# iqn_dio2 register map
Vendor: Texas Instruments
Peripheral module from a debugger description file (folder Keystone2).
Registers are 32-bit, read-only, no defined reset value unless marked. A register's access mark holds for its fields unless they carry their own. Offsets are as the file gives them; lines under a group give offsets from that group; [hi:lo] are bit positions; {n}, {i} and the like mark numbered series; 'fields as' and 'values as' point back to an identical list; <NAME> marks a mode.

## IQN_DIO2 (part 1 of 2)
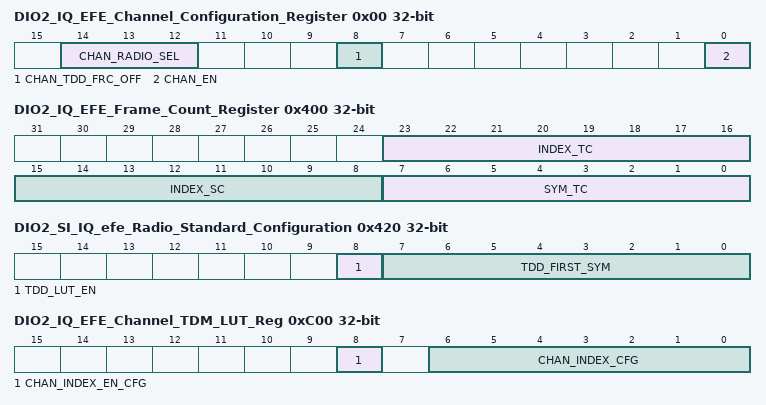
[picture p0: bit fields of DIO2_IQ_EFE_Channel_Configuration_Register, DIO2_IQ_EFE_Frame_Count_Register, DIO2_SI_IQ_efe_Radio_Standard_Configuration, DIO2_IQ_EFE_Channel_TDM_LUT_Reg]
0x00 DIO2_IQ_EFE_Channel_Configuration_Register rw — (1 of 1, stride 0)
  [14:12] CHAN_RADIO_SEL — Assigns each channel to one of eight radio standard groups. i.e. radio standard 0 may be LTE 20MHz
  [8] CHAN_TDD_FRC_OFF — Alternate TDD mode for controlling TDD also used for GSM Base Band Hopping. APP SW controls updates this bit each symbol of time to control whether the next symbol will be TDD OFF. TDD OFF channels generate no Ingress DMA traffic and expect no Egress DMA
  [0] CHAN_EN — Enable channel
0x200 DIO2_IQ_EFE_Configuration_Register rw — (1 of 1, stride 0)
  [0] LOOPBACK_EN — (TI use Only) 0x1: Ingress data from ICC is looped back to Egress data to ICC. DMA traffic is unused. (i.e. for purpose of early DFE only testing)
0x240 DIO2_IQ_EFE_Global_Enable_Set_Reg wo — (1 of 1, stride 0)
  [31:0] DONT_CARE — A write of any value to this register which sets (enables) global enable
0x244 DIO2_IQ_EFE_Global_Enable_Clear_Reg wo — (1 of 1, stride 0)
  [31:0] DONT_CARE — A write of any value to this register which clears (enables) global enable
0x248 DIO2_IQ_EFE_Global_Enable_Status — (1 of 1, stride 0)
  [0] ENABLE — 0x1: efe_ON 0x0:efe_OFF
0x260 DIO2_IQ_EFE_Channel_ON_Status_Reg — (1 of 1, stride 0)
  [15:0] CHAN_ON — 0x1: CHAN_ON 0x0:CHAN_OFF
0x280 DIO2_IQ_EFE_IN_Packet_Status_Registers — (1 of 1, stride 0)
  [15:0] IN_PKT — 0x1: IN_PKT 0x0:OUT_PKT
0x2A0 DIO2_IQ_EFE_DMA_SYNC_Status_Registers — (1 of 1, stride 0)
  [15:0] DMA_SYNC — 0x1: DMA synchronized to radio timing for this channel 0x0:DMA not synchronized to radio timing for this channel. Channel is in in re-sync mode.
0x400 DIO2_IQ_EFE_Frame_Count_Register rw — (1 of 1, stride 0)
  [23:16] INDEX_TC — Radio Framing Counter. Index Counter Terminal Count. Index counter terminal count which is the last value of the Index Counter before it wraps. For simple use case, program same as frm_sym_tc.
  [15:8] INDEX_SC — Radio Framing Counter. Index Counter Starting Location. Starting location of the Sample Terminal Count LUT loaded into the Index Counter when it first starts and each time it wraps. Depending on the radio standard, the index will wrap once per radio frame
  [7:0] SYM_TC — Radio Framing Counter. Symbol Count. Number of symbols per frame programmed as a terminal count.
0x420 DIO2_SI_IQ_efe_Radio_Standard_Configuration rw — (1 of 1, stride 0)
  [8] TDD_LUT_EN — Enable TDD
  [7:0] TDD_FIRST_SYM — Selects first symbol to start TDD
{0x440+0x20*i} DIO2_IQ_efe_Radio_Standard_{i}_TDD_ENABLE_LUT rw (i=0..7) — (1 of 1, stride 0)
  [31:0] TDD_EN — enables/disables DMA of whole symbols (PktDMA packets). Program as 0xffff for most applications.
0x600 DIO2_IQ_EFE_Channel_AXC_Offset_Reg rw — (1 of 16, stride 4)
  [19:0] AXC_OFFSET — AxC-by-AxC delay control. Allows different timing alignments for each AxC. DIO, AID applicactions this is a 4 sample offset relatvie to the group or TDM of AxC. AIL CPRI, this is a sample offset relative to the CPRI AxC Group. AIL OBSAI, this is a Radio
0x800 DIO2_IQ_EFE_AxC_Framing_Sample_Terminal_Count rw — (1 of 256, stride 4)
  [17:0] SAMP_TC — Radio Framing Counter. Number of samples (4 Bytes) per radio symbol programmed as a terminal count
0xC00 DIO2_IQ_EFE_Channel_TDM_LUT_Reg rw — (1 of 256, stride 4)
  [8] CHAN_INDEX_EN_CFG — TDM Channel Index LUT Enable
  [6:0] CHAN_INDEX_CFG — TDM Channel Index
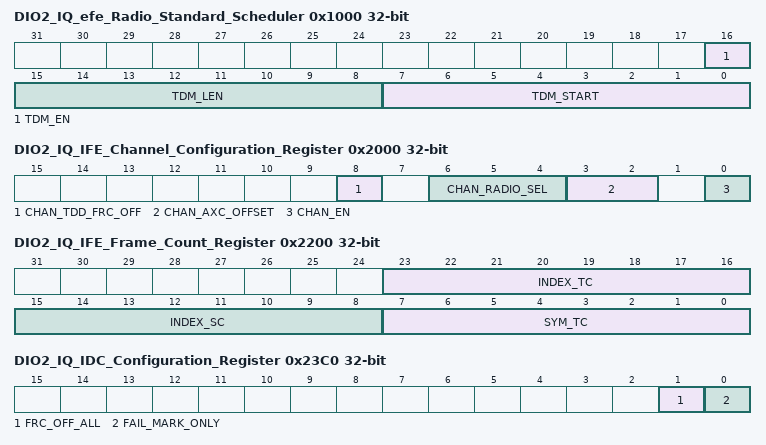
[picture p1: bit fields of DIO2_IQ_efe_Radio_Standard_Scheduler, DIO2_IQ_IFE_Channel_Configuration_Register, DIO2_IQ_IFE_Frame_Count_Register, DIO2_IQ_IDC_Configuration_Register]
0x1000 DIO2_IQ_efe_Radio_Standard_Scheduler rw — (1 of 1, stride 0)
  [16] TDM_EN — EFE Scheculer Enable TDM
  [15:8] TDM_LEN — EFE Scheduler TDM Length
  [7:0] TDM_START — EFE Scheduler TDM Starting address in LUT
0x2000 DIO2_IQ_IFE_Channel_Configuration_Register rw — (1 of 1, stride 0)
  [8] CHAN_TDD_FRC_OFF — Forces a channel into the TDD OFF state on the next symbol after it is set to a 1 regardless of the TDD configuration of the radio standard variant the channel is assigned to.
  [6:4] CHAN_RADIO_SEL — Radio Standard Select
  [3:2] CHAN_AXC_OFFSET — AxC Offset
  [0] CHAN_EN — Enable channel
0x2200 DIO2_IQ_IFE_Frame_Count_Register rw — (1 of 1, stride 0)
  [23:16] INDEX_TC — Radio Framing Counter. Index Counter Terminal Count. Index counter terminal count which is the last value of the Index Counter before it wraps. For simple use case, program same as frm_sym_tc.
  [15:8] INDEX_SC — Radio Framing Counter. Index Counter Starting Location. Starting location of the Sample Terminal Count LUT loaded into the Index Counter when it first starts and each time it wraps.
  [7:0] SYM_TC — Radio Framing Counter. Symbol Count. Number of symbols per frame programmed as a terminal count.
0x2220 DIO2_IQ_IFE_Radio_Standard_Configuration rw — (1 of 1, stride 0)
  [0] TDD_LUT_EN — Enable TDD
{0x2240+0x20*i} DIO2_IQ_IFE_Radio_Standard_{i}_TDD_ENABLE_LUT rw (i=0..7) — (1 of 1, stride 0)
  fields as DIO2_IQ_efe_Radio_Standard_0_TDD_ENABLE_LUT
0x2340 DIO2_IQ_IFE_Global_Enable_Set_Reg wo — (1 of 1, stride 0)
  fields as DIO2_IQ_EFE_Global_Enable_Set_Reg
0x2344 DIO2_IQ_IFE_Global_Enable_Clear_Reg wo — (1 of 1, stride 0)
  fields as DIO2_IQ_EFE_Global_Enable_Clear_Reg
0x2348 DIO2_IQ_IFE_Global_Enable_Status — (1 of 1, stride 0)
  [0] ENABLE — 0x1: ife_ON 0x0:ife_OFF
0x2350 DIO2_IQ_IFE_Channel_ON_Status_Reg — (1 of 1, stride 0)
  [15:0] CHAN_ON — 0x1: CHAN_ON 0x0:CHAN_OFF
0x2360 DIO2_IQ_IFE_IN_Packet_Status_Registers — (1 of 1, stride 0)
  [15:0] IN_PKT — 0x1: IN_PKT 0x0:OUT_PKT
0x2384 DIO2_IQ_IDC_Status_Register — (1 of 1, stride 0)
  [0] EMPTY — Empty indicator for both the PSI Staging FIFO and the CDC FIFO
0x2390 DIO2_IQ_IDC_In_Packet_Status_Register — (1 of 1, stride 0)
  [15:0] INPKT — Per-channel in packet status bits where a 0 indicates that the channel is not actively processing a packet and a 1 indicates that it is actively processing a packet. The inpkt to channel assignment is such that inpkt\[0\] is associated with channel 0 and
0x23C0 DIO2_IQ_IDC_Configuration_Register rw — (1 of 1, stride 0)
  [1] FRC_OFF_ALL — Forces off all Ingress channels without waiting for an end of symbol or time slot. All open packets are automatically closed by creating an EOP for each open packet
  [0] FAIL_MARK_ONLY — Controls how the IDC handles packet errors detected by IFE
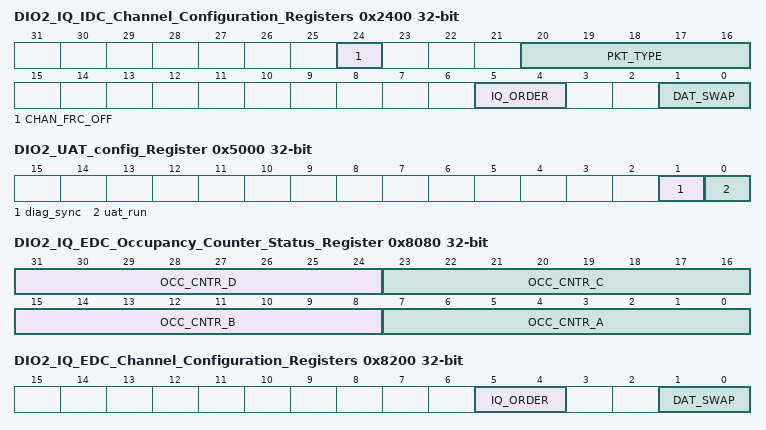
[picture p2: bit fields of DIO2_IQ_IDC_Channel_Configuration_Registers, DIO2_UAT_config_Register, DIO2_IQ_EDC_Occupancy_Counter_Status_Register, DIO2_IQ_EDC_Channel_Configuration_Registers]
0x2400 DIO2_IQ_IDC_Channel_Configuration_Registers rw — (1 of 1, stride 0)
  [24] CHAN_FRC_OFF — Forces off all channel without waiting for an end of symbol or time slot. If channel has an open packet it is automatically closed by creating an EOP
  [20:16] PKT_TYPE — Programmable packet type that is inserted into pkt_type field of PKTDMA Info Word 0.
  [5:4] IQ_ORDER — IQ swapping control.
  [1:0] DAT_SWAP — Byte swapping control.
0x2800 DIO2_IQ_IFE_AxC_Framing_Sample_Terminal_Count rw — (1 of 256, stride 4)
  fields as DIO2_IQ_EFE_AxC_Framing_Sample_Terminal_Count
0x5000 DIO2_UAT_config_Register rw — (1 of 1, stride 0)
  [1] diag_sync — diag_sync = 1 starts the BCN and RAD counters if uat_run is set and an AT sync is received. This is only used in simulation and for diagnostics
  [0] uat_run — UAT run starts the BCN and RAD counters free running
0x5004 DIO2_UAT_BCN_terminal_count_Register rw — (1 of 1, stride 0)
  [24:0] val — UAT BCN terminal count. BCN counts from zero to this limit and wraps to zero. Program as 2,457,599 for sys_clk=245.76MHz and 3,071,999 for sys_clk=307.2MHz
0x5008 DIO2_UAT_BCN_offset_Register rw — (1 of 1, stride 0)
  [24:0] val — Offset correction to the raw uAT BCN counter. Used to correct the alignment of the local uAT BCN to the master AT2 BCN. BCN is initially randomly started. SW uses uat_sync_bcn_capture_sts rd_val to calculate offset correction factor. This correction
0x500C DIO2_UAT_SYNC_BCN_capture_Register — (1 of 1, stride 0)
  [24:0] rd_val — uAT raw BCN value captured each frame boundary of AT2 master BCN. Used to calculate uAT BCN offset value for the purpose of aligning uAT to AT2 BCN.
0x5080 DIO2_UAT_RADT_terminal_count_Register rw — (1 of 8, stride 16)
  [24:0] val — UAT RADT terminal count. (i.e. 2,457,599 for WCDMA with sys_clk=245.76MHz)
0x5084 DIO2_UAT_RADT_offset_Register rw — (1 of 8, stride 16)
  [24:0] val — UAT RADT offset. Value which is added to the raw RADT as a timing correction. RadT is initially randomly started, SW uses radt_capture value to calculate offset correction factor. This correction factor will be Frame size
0x5088 DIO2_UAT_SYNC_RADT_capture_Register — (1 of 8, stride 16)
  [24:0] rd_val — UAT RADT sync capture captures the offset RADT count when a uat_mst_slv_sync from the AT occurs. Used by SW to determine correct RADT offset to apply.
0x5100 DIO2_UAT_RADT_terminal_count_Register rw — (1 of 8, stride 16)
  fields as DIO2_UAT_RADT_terminal_count_Register
0x5104 DIO2_UAT_RADT_offset_Register rw — (1 of 8, stride 16)
  fields as DIO2_UAT_RADT_offset_Register
0x5108 DIO2_UAT_SYNC_RADT_capture_Register — (1 of 8, stride 16)
  fields as DIO2_UAT_SYNC_RADT_capture_Register
0x5200 DIO2_UAT_RADT_event_compare_Register rw — (1 of 22, stride 8)
  [24:0] val — UAT RADT event compare per RADT. When compare value equals RADT count, frame rate event is generated. Also periodic event (i.e. 4SAMP) is started. The 0 to 7 are for si egress, 8 to 15 for si ingress, 16 to 18 for dio egress, 19 to 21 for dio ingress
0x5204 DIO2_UAT_RADT_event_clock_count_tc_Register rw — (1 of 22, stride 8)
  [15:0] val — UAT RADT event clock counter terminal count controls spacing of the periodic strobe (i.e. 4SAMP). Once the uat_evt_radt_cmp_cfg equals the RADT, the period strobe will fire and re-fire every time a clock counter reaches this terminal count. The The 0 to 7
0x5300 DIO2_UAT_DIO_egress_RADT_terminal_count rw — (1 of 3, stride 16)
  [24:0] val — (DIO use only) UAT DIO egress RADT terminal count. (i.e. 2,457,599 for WCDMA with sys_clk=245.76MHz)
0x5304 DIO2_UAT_DIO_egress_RADT_offset_Register rw — (1 of 3, stride 16)
  [24:0] val — (DIO use only) UAT DIO egress RADT offset. Value which is added to the raw RADT as a timing correction. RadT is initially randomly started, SW uses radt_capture value to calculate offset correction factor. This correction factor will be Frame size
0x5308 DIO2_UAT_SYNC_DIO_egress_RADT_capture_Register — (1 of 3, stride 16)
  [24:0] rd_val — (DIO use only)UAT DIO egress RADT sync capture captures the offset RADT count when a uat_mst_slv_sync from the AT occurs. Used by SW to determine correct RADT offset to apply.
0x5340 DIO2_UAT_DIO_ingress_RADT_terminal_count rw — (1 of 3, stride 16)
  [24:0] val — (DIO use only) UAT DIO ingress RADT terminal count. (i.e. 2,457,599 for WCDMA with sys_clk=245.76MHz)
0x5344 DIO2_UAT_DIO_ingress_RADT_offset_Register rw — (1 of 3, stride 16)
  [24:0] val — (DIO use only) UAT DIO ingress RADT offset. Value which is added to the raw RADT as a timing correction. RadT is initially randomly started, SW uses radt_capture value to calculate offset correction factor. This correction factor will be Frame size
0x5348 DIO2_UAT_SYNC_DIO_ingress_RADT_capture_Register — (1 of 3, stride 16)
  [24:0] rd_val — (DIO use only) UAT DIO ingress RADT sync capture captures the offset.
0x8000 DIO2_IQ_EDC_Configuration_Register rw — (1 of 1, stride 0)
  [0] PSI_ERR_CHK_DISABLE — Controls how the EDC handles packet errors detected by efe
0x8004 DIO2_IQ_EDC_SOP_Counter_Status_Register — (1 of 1, stride 0)
  [23:0] SOP_CNT — Count of the number of SOPs seen by the IQ EDC
0x8008 DIO2_IQ_EDC_EOP_Counter_Status_Register — (1 of 1, stride 0)
  [23:0] EOP_CNT — Count of the number of EOPs seen by the IQ EDC
0x8080 DIO2_IQ_EDC_Occupancy_Counter_Status_Register — (1 of 1, stride 0)
  [31:24] OCC_CNTR_D — Occupancy Counter for register D for this address
  [23:16] OCC_CNTR_C — Occupancy Counter for register C for this address
  [15:8] OCC_CNTR_B — Occupancy Counter for register B for this address
  [7:0] OCC_CNTR_A — Occupancy Counter for register A for this address
0x8200 DIO2_IQ_EDC_Channel_Configuration_Registers rw — (1 of 1, stride 0)
  [5:4] IQ_ORDER — IQ swapping control.
  [1:0] DAT_SWAP — Byte swapping control.
0xA000 DIO2_IQ_IDC_Rate_Control_Configuration_Register rw — (1 of 1, stride 0)
  [3:0] RATE — Rate Controller will allow the IDC to create RATE+1 active requests on the PSI bus within a 32 clock cycle window. As an example, a value of 7 will allow the IDC to create 8 active requests within a 32-clock cycle window which uses 25% of the PSI bus.
0xA004 DIO2_IQ_IDC_SOP_Counter_Register — (1 of 1, stride 0)
  [23:0] SOP_CNT — Wrapping count of SOPs sent on PSI.
0xA008 DIO2_IQ_IDC_EOP_Counter_Register — (1 of 1, stride 0)
  [23:0] EOP_CNT — Wrapping count of EOPs sent on PSI.
0x10000 DIO2_DIO_Ingress_Global_Enable_Set_Register wo — (1 of 1, stride 0)
  [31:0] DONT_CARE — A write of any value to this register sets the global enable for the Ingress DIO
0x10004 DIO2_DIO_Ingress_Global_Enable_Clear_Register wo — (1 of 1, stride 0)
  [31:0] DONT_CARE — A write of any value to this register clears the global enable for the Ingress DIO
0x10008 DIO2_DIO_Ingress_Global_Enable_Status_Register — (1 of 1, stride 0)
  [0] ENABLE — 0x1: Ingress DIO ON 0x0:Ingress DIO OFF
0x10010 DIO2_DIO_Egress_Global_Enable_Set_Register wo — (1 of 1, stride 0)
  [31:0] DONT_CARE — A write of any value to this register sets the global enable for the Egress DIO
0x10014 DIO2_DIO_Egress_Global_Enable_Clear_Register wo — (1 of 1, stride 0)
  [31:0] DONT_CARE — A write of any value to this register clears the global enable for the Egress DIO
0x10018 DIO2_DIO_Egress_Global_Enable_Status_Register — (1 of 1, stride 0)
  [0] ENABLE — 0x1: Egress DIO ON 0x0:Egress DIO OFF
0x10020 DIO2_DIO_Data_Trace_Global_Enable_Set_Register wo — (1 of 1, stride 0)
  [31:0] DONT_CARE — A write of any value to this register sets the global enable for the Data Trace DIO
0x10024 DIO2_DIO_Data_Trace_Global_Enable_Clear wo — (1 of 1, stride 0)
  [31:0] DONT_CARE — A write of any value to this register clears the global enable for the Data Trace DIO
0x10028 DIO2_DIO_Data_Trace_Global_Enable_Status — (1 of 1, stride 0)
  [0] ENABLE — 0x1: Data Trace DIO ON 0x0:Data Trace DIO OFF
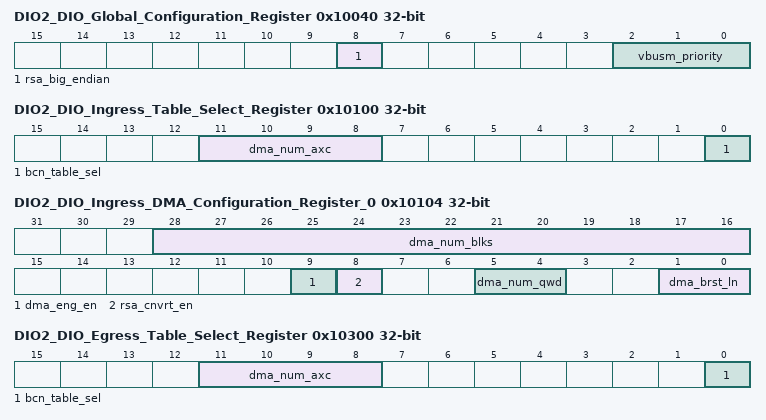
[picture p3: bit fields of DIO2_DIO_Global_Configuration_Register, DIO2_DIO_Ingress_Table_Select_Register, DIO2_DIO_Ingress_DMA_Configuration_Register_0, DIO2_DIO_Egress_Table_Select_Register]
0x10040 DIO2_DIO_Global_Configuration_Register rw — (1 of 1, stride 0)
  [8] rsa_big_endian — Sets RSA Data Format Conversian Endeness
  [2:0] vbusm_priority — Sets vbusm cpriority and cepriority for both reads and writes (priority 0 = highest,7 = lowest, reset value = 0 (highest priority))
0x10100 DIO2_DIO_Ingress_Table_Select_Register rw — (1 of 3, stride 64)
  [11:8] dma_num_axc — Sets the number of AxCs (i.e. 0 to 15 i.e. 1 to 16 AxCs).
  [0] bcn_table_sel — Selects which buffer channel number table for the DMA engine to use
0x10104 DIO2_DIO_Ingress_DMA_Configuration_Register_0 rw — (1 of 3, stride 64)
  [28:16] dma_num_blks — Set the number of data blocks to transfer before wrapping back to dma_base_addr. (1 to 8191 = 2 to 8192). Note: (num_blks + 1) must be an even number.
  [9] dma_eng_en — Enable DMA engine.
  [8] rsa_cnvrt_en — Ingress RSA data conversion enable per DMA engine.
  [5:4] dma_num_qwd — Sets the number of quad words per AxC.
  [1:0] dma_brst_ln — Sets the maximum DMA burst length.
0x10108 DIO2_DIO_Ingress_DMA_Configuration_Register_1 rw — (1 of 3, stride 64)
  [11:0] dma_blk_addr_stride — Sets the DMA block address stride (in multiples of 0x10).
0x10200 DIO2_DIO_Ingress_AxC_Offset_Reg rw — (1 of 16, stride 4)
  [2:0] dio_i_axc_4samp_offset — DIO Ingress AxC offset within a circular buffer.
0x10300 DIO2_DIO_Egress_Table_Select_Register rw — (1 of 3, stride 64)
  fields as DIO2_DIO_Ingress_Table_Select_Register
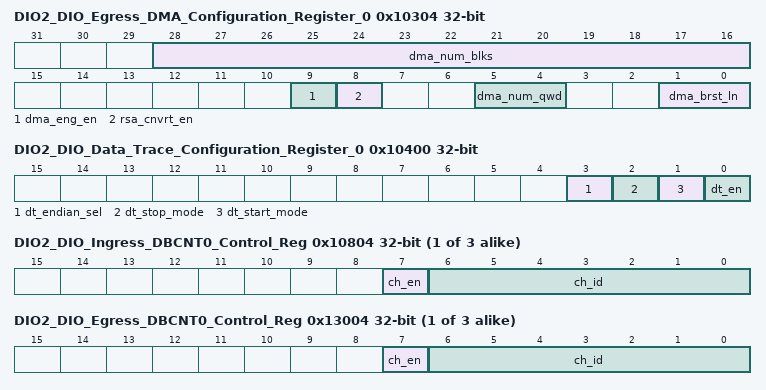
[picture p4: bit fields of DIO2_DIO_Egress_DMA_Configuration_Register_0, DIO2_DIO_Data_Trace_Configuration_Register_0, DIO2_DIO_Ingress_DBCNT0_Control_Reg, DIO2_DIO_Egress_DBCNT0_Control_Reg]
0x10304 DIO2_DIO_Egress_DMA_Configuration_Register_0 rw — (1 of 3, stride 64)
  [28:16] dma_num_blks — Set the number of data blocks to transfer before wrapping back to dma_base_addr. (1 to 8191 = 2 to 8192). Note: (num_blks + 1) must be an even number.
  [9] dma_eng_en — Enable DMA engine.
  [8] rsa_cnvrt_en — Egress RSA data conversion enable per channel.
  [5:4] dma_num_qwd — Sets the number of quad words per AxC.
  [1:0] dma_brst_ln — Sets the maximum DMA burst length.
0x10308 DIO2_DIO_Egress_DMA_Configuration_Register_1 rw — (1 of 3, stride 64)
  fields as DIO2_DIO_Ingress_DMA_Configuration_Register_1
0x10400 DIO2_DIO_Data_Trace_Configuration_Register_0 rw — (1 of 1, stride 0)
  [3] dt_endian_sel — Selects Data Trace Endian mode.
  [2] dt_stop_mode — Selects Data Trace stopping mode.
  [1] dt_start_mode — Selects Data Trace start operating mode.
  [0] dt_en — Enables Data Trace DMA
0x10404 DIO2_DIO_Data_Trace_Configuration_Register_1 rw — (1 of 1, stride 0)
  [27:0] dt_dma_base_addr — Sets the destination VBUS base address (upper 28 bits of 32 bit data bus) for data trace receive data. The base address must be programmed BEFORE dt_en is set.
0x10408 DIO2_DIO_Data_Trace_Configuration_Register_2 rw — (1 of 1, stride 0)
  [17:0] dt_dma_wrap — Sets the number of burst transfers before the destination address wraps back to the base address. Each burst transfer is 4 Quad Words.
0x1040C DIO2_DIO_Data_Trace_Start_Register wo — (1 of 1, stride 0)
  [31:0] DONT_CARE — A write of any value to this register will start Data Trace operation if dt_en = 0.
0x10410 DIO2_DIO_Data_Trace_Operational_Status_Register — (1 of 1, stride 0)
  [0] dt_in_progress — 0x0:Data Trace DIO Idle 0x1: Data Trace DIO data capture in progress
{0x10800+0x800*i} DIO2_DIO_Ingress_DBCNT{i}_Base_Address_Reg rw (i=0..2) — (1 of 32, stride 8)
  [27:0] dma_vbus_base_addr_axc — DIO Ingress DBCNT {i}
{0x10804+0x800*i} DIO2_DIO_Ingress_DBCNT{i}_Control_Reg rw (i=0..2) — (1 of 32, stride 8)
  [7] ch_en — DIO Ingress DBCNT {i}
  [6:0] ch_id — DIO Ingress DBCNT {i}
0x12800 DIO2_DIO_Egress_AxC_Offset_Reg rw — (1 of 16, stride 4)
  [16:0] dio_e_axc_4samp_offset — DIO Egress AxC offset from Frame Boundary in 4 sample (1 QW) increments
{0x13000+0x800*i} DIO2_DIO_Egress_DBCNT{i}_Base_Address_Reg rw (i=0..2) — (1 of 32, stride 8)
  [27:0] dma_vbus_base_addr_axc — DIO Egress DBCNT {i}
{0x13004+0x800*i} DIO2_DIO_Egress_DBCNT{i}_Control_Reg rw (i=0..2) — (1 of 32, stride 8)
  [7] ch_en — DIO Egress DBCNT {i}
  [6:0] ch_id — DIO Egress DBCNT {i}
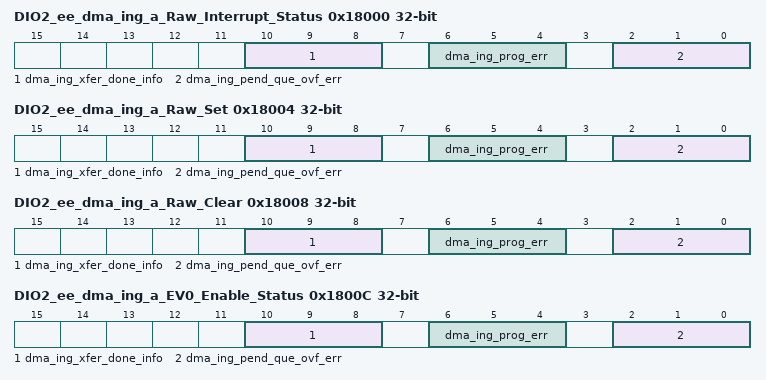
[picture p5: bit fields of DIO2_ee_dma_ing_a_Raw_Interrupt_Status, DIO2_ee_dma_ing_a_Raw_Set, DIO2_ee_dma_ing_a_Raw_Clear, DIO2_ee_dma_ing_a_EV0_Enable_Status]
0x18000 DIO2_ee_dma_ing_a_Raw_Interrupt_Status — (1 of 1, stride 0)
  [10:8] dma_ing_xfer_done_info — Ingress DMA block transfer complete detected per DMA engine
  [6:4] dma_ing_prog_err — Ingress DMA Programming error detected per DMA engine
  [2:0] dma_ing_pend_que_ovf_err — Ingress DMA engine(s) error i.e. the trigger pending queue overflowed.
0x18004 DIO2_ee_dma_ing_a_Raw_Set wo — (1 of 1, stride 0)
  [10:8] dma_ing_xfer_done_info — Sets the corresponding bit in the raw_status register when set. Write only, self-clears.
  [6:4] dma_ing_prog_err — Sets the corresponding bit in the raw_status register when set. Write only, self-clears.
  [2:0] dma_ing_pend_que_ovf_err — Sets the corresponding bit in the raw_status register when set. Write only, self-clears.
0x18008 DIO2_ee_dma_ing_a_Raw_Clear wo — (1 of 1, stride 0)
  [10:8] dma_ing_xfer_done_info — Clears the corresponding bit in the raw_status register when set. Write only, self-clears.
  [6:4] dma_ing_prog_err — Clears the corresponding bit in the raw_status register when set. Write only, self-clears.
  [2:0] dma_ing_pend_que_ovf_err — Clears the corresponding bit in the raw_status register when set. Write only, self-clears.
0x1800C DIO2_ee_dma_ing_a_EV0_Enable_Status — (1 of 1, stride 0)
  [10:8] dma_ing_xfer_done_info — When set allows the corresponding bit in the raw_status register to generate the intr_sts interrupt. Read only.
  [6:4] dma_ing_prog_err — When set allows the corresponding bit in the raw_status register to generate the intr_sts interrupt. Read only.
  [2:0] dma_ing_pend_que_ovf_err — When set allows the corresponding bit in the raw_status register to generate the intr_sts interrupt. Read only.
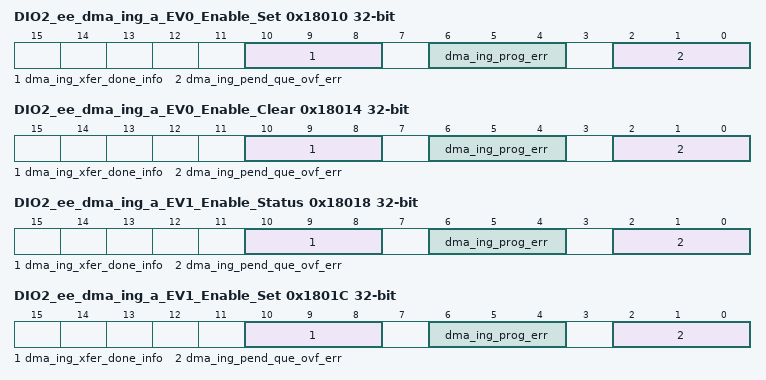
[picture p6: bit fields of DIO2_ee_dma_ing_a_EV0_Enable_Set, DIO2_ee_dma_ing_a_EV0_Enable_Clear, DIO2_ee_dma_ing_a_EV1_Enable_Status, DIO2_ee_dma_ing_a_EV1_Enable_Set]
0x18010 DIO2_ee_dma_ing_a_EV0_Enable_Set wo — (1 of 1, stride 0)
  [10:8] dma_ing_xfer_done_info — Sets the corresponding bit in the enable register when set. Write only, self-clears.
  [6:4] dma_ing_prog_err — Sets the corresponding bit in the enable register when set. Write only, self-clears.
  [2:0] dma_ing_pend_que_ovf_err — Sets the corresponding bit in the enable register when set. Write only, self-clears.
0x18014 DIO2_ee_dma_ing_a_EV0_Enable_Clear wo — (1 of 1, stride 0)
  [10:8] dma_ing_xfer_done_info — Clears the corresponding bit in the enable register when set. Write only, self-clears.
  [6:4] dma_ing_prog_err — Clears the corresponding bit in the enable register when set. Write only, self-clears.
  [2:0] dma_ing_pend_que_ovf_err — Clears the corresponding bit in the enable register when set. Write only, self-clears.
0x18018 DIO2_ee_dma_ing_a_EV1_Enable_Status — (1 of 1, stride 0)
  [10:8] dma_ing_xfer_done_info — When set allows the corresponding bit in the raw_status register to generate the intr1_sts interrupt. Read only.
  [6:4] dma_ing_prog_err — When set allows the corresponding bit in the raw_status register to generate the intr1_sts interrupt. Read only.
  [2:0] dma_ing_pend_que_ovf_err — When set allows the corresponding bit in the raw_status register to generate the intr1_sts interrupt. Read only.
0x1801C DIO2_ee_dma_ing_a_EV1_Enable_Set wo — (1 of 1, stride 0)
  [10:8] dma_ing_xfer_done_info — Sets the corresponding bit in the intr1_status register when set. Write only, self-clears.
  [6:4] dma_ing_prog_err — Sets the corresponding bit in the intr1_status register when set. Write only, self-clears.
  [2:0] dma_ing_pend_que_ovf_err — Sets the corresponding bit in the intr1_status register when set. Write only, self-clears.
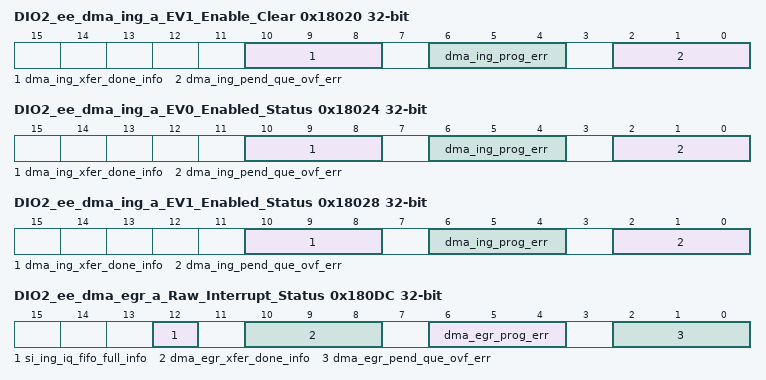
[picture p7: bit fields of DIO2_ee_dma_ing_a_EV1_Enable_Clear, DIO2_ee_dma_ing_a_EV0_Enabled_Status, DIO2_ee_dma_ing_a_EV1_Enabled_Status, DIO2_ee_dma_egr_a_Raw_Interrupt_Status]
0x18020 DIO2_ee_dma_ing_a_EV1_Enable_Clear wo — (1 of 1, stride 0)
  [10:8] dma_ing_xfer_done_info — Clears the corresponding bit in the intr1_status register when set. Write only, self-clears.
  [6:4] dma_ing_prog_err — Clears the corresponding bit in the intr1_status register when set. Write only, self-clears.
  [2:0] dma_ing_pend_que_ovf_err — Clears the corresponding bit in the intr1_status register when set. Write only, self-clears.
0x18024 DIO2_ee_dma_ing_a_EV0_Enabled_Status — (1 of 1, stride 0)
  [10:8] dma_ing_xfer_done_info — AND-ed raw_status bits with the corresponding bit in the enable_status register. Read only.
  [6:4] dma_ing_prog_err — AND-ed raw_status bits with the corresponding bit in the enable_status register. Read only.
  [2:0] dma_ing_pend_que_ovf_err — AND-ed raw_status bits with the corresponding bit in the enable_status register. Read only.
0x18028 DIO2_ee_dma_ing_a_EV1_Enabled_Status — (1 of 1, stride 0)
  [10:8] dma_ing_xfer_done_info — AND-ed raw_status bits with the corresponding bit in the intr1_status register. Read only.
  [6:4] dma_ing_prog_err — AND-ed raw_status bits with the corresponding bit in the intr1_status register. Read only.
  [2:0] dma_ing_pend_que_ovf_err — AND-ed raw_status bits with the corresponding bit in the intr1_status register. Read only.
0x1802C DIO2_ee_dma_ing_b_Raw_Interrupt_Status — (1 of 1, stride 0)
  [15:0] dma_ing_buf_ovf_err — Ingress Data Buffer overflow per channel
0x18030 DIO2_ee_dma_ing_b_Raw_Set wo — (1 of 1, stride 0)
  [15:0] dma_ing_buf_ovf_err — Sets the corresponding bit in the raw_status register when set. Write only, self-clears.
0x18034 DIO2_ee_dma_ing_b_Raw_Clear wo — (1 of 1, stride 0)
  [15:0] dma_ing_buf_ovf_err — Clears the corresponding bit in the raw_status register when set. Write only, self-clears.
0x18038 DIO2_ee_dma_ing_b_EV0_Enable_Status — (1 of 1, stride 0)
  [15:0] dma_ing_buf_ovf_err — When set allows the corresponding bit in the raw_status register to generate the intr_sts interrupt. Read only.
0x1803C DIO2_ee_dma_ing_b_EV0_Enable_Set wo — (1 of 1, stride 0)
  [15:0] dma_ing_buf_ovf_err — Sets the corresponding bit in the enable register when set. Write only, self-clears.
0x18040 DIO2_ee_dma_ing_b_EV0_Enable_Clear wo — (1 of 1, stride 0)
  [15:0] dma_ing_buf_ovf_err — Clears the corresponding bit in the enable register when set. Write only, self-clears.
0x18044 DIO2_ee_dma_ing_b_EV1_Enable_Status — (1 of 1, stride 0)
  [15:0] dma_ing_buf_ovf_err — When set allows the corresponding bit in the raw_status register to generate the intr1_sts interrupt. Read only.
0x18048 DIO2_ee_dma_ing_b_EV1_Enable_Set wo — (1 of 1, stride 0)
  [15:0] dma_ing_buf_ovf_err — Sets the corresponding bit in the intr1_status register when set. Write only, self-clears.
0x1804C DIO2_ee_dma_ing_b_EV1_Enable_Clear wo — (1 of 1, stride 0)
  [15:0] dma_ing_buf_ovf_err — Clears the corresponding bit in the intr1_status register when set. Write only, self-clears.
0x18050 DIO2_ee_dma_ing_b_EV0_Enabled_Status — (1 of 1, stride 0)
  [15:0] dma_ing_buf_ovf_err — AND-ed raw_status bits with the corresponding bit in the enable_status register. Read only.
0x18054 DIO2_ee_dma_ing_b_EV1_Enabled_Status — (1 of 1, stride 0)
  [15:0] dma_ing_buf_ovf_err — AND-ed raw_status bits with the corresponding bit in the intr1_status register. Read only.
0x180DC DIO2_ee_dma_egr_a_Raw_Interrupt_Status — (1 of 1, stride 0)
  [12] si_ing_iq_fifo_full_info — PSI Staging FIFO Full i.e. back pressuring the egress data path including the VBUSM
  [10:8] dma_egr_xfer_done_info — Egress DMA block transfer complete detected per DMA engine
  [6:4] dma_egr_prog_err — Egress DMA Programming error detected per DMA engine
  [2:0] dma_egr_pend_que_ovf_err — Egress DMA engine(s) error i.e. the trigger pending queue overflowed.
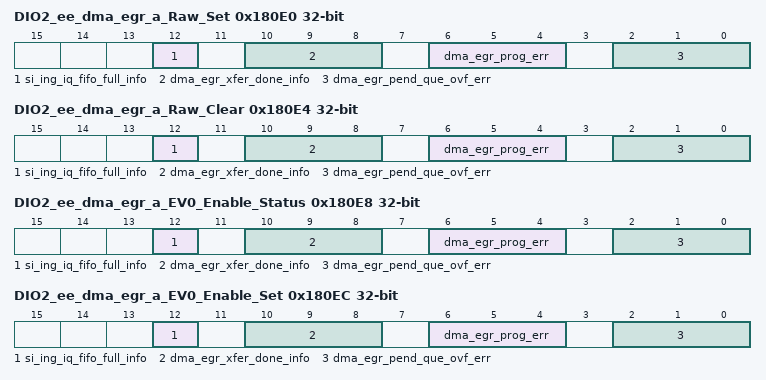
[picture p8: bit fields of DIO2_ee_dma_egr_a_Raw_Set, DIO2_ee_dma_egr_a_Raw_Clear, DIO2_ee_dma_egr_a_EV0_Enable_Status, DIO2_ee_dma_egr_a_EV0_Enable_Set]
0x180E0 DIO2_ee_dma_egr_a_Raw_Set wo — (1 of 1, stride 0)
  [12] si_ing_iq_fifo_full_info — Sets the corresponding bit in the raw_status register when set. Write only, self-clears.
  [10:8] dma_egr_xfer_done_info — Sets the corresponding bit in the raw_status register when set. Write only, self-clears.
  [6:4] dma_egr_prog_err — Sets the corresponding bit in the raw_status register when set. Write only, self-clears.
  [2:0] dma_egr_pend_que_ovf_err — Sets the corresponding bit in the raw_status register when set. Write only, self-clears.
0x180E4 DIO2_ee_dma_egr_a_Raw_Clear wo — (1 of 1, stride 0)
  [12] si_ing_iq_fifo_full_info — Clears the corresponding bit in the raw_status register when set. Write only, self-clears.
  [10:8] dma_egr_xfer_done_info — Clears the corresponding bit in the raw_status register when set. Write only, self-clears.
  [6:4] dma_egr_prog_err — Clears the corresponding bit in the raw_status register when set. Write only, self-clears.
  [2:0] dma_egr_pend_que_ovf_err — Clears the corresponding bit in the raw_status register when set. Write only, self-clears.
0x180E8 DIO2_ee_dma_egr_a_EV0_Enable_Status — (1 of 1, stride 0)
  [12] si_ing_iq_fifo_full_info — When set allows the corresponding bit in the raw_status register to generate the intr_sts interrupt. Read only.
  [10:8] dma_egr_xfer_done_info — When set allows the corresponding bit in the raw_status register to generate the intr_sts interrupt. Read only.
  [6:4] dma_egr_prog_err — When set allows the corresponding bit in the raw_status register to generate the intr_sts interrupt. Read only.
  [2:0] dma_egr_pend_que_ovf_err — When set allows the corresponding bit in the raw_status register to generate the intr_sts interrupt. Read only.
0x180EC DIO2_ee_dma_egr_a_EV0_Enable_Set wo — (1 of 1, stride 0)
  [12] si_ing_iq_fifo_full_info — Sets the corresponding bit in the enable register when set. Write only, self-clears.
  [10:8] dma_egr_xfer_done_info — Sets the corresponding bit in the enable register when set. Write only, self-clears.
  [6:4] dma_egr_prog_err — Sets the corresponding bit in the enable register when set. Write only, self-clears.
  [2:0] dma_egr_pend_que_ovf_err — Sets the corresponding bit in the enable register when set. Write only, self-clears.
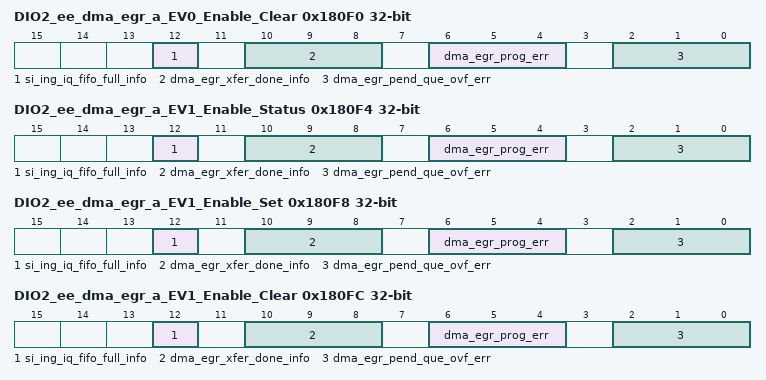
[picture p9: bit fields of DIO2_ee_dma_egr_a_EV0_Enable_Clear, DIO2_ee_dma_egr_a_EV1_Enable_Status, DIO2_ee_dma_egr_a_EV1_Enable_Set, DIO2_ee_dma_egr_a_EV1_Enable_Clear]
0x180F0 DIO2_ee_dma_egr_a_EV0_Enable_Clear wo — (1 of 1, stride 0)
  [12] si_ing_iq_fifo_full_info — Clears the corresponding bit in the enable register when set. Write only, self-clears.
  [10:8] dma_egr_xfer_done_info — Clears the corresponding bit in the enable register when set. Write only, self-clears.
  [6:4] dma_egr_prog_err — Clears the corresponding bit in the enable register when set. Write only, self-clears.
  [2:0] dma_egr_pend_que_ovf_err — Clears the corresponding bit in the enable register when set. Write only, self-clears.
0x180F4 DIO2_ee_dma_egr_a_EV1_Enable_Status — (1 of 1, stride 0)
  [12] si_ing_iq_fifo_full_info — When set allows the corresponding bit in the raw_status register to generate the intr1_sts interrupt. Read only.
  [10:8] dma_egr_xfer_done_info — When set allows the corresponding bit in the raw_status register to generate the intr1_sts interrupt. Read only.
  [6:4] dma_egr_prog_err — When set allows the corresponding bit in the raw_status register to generate the intr1_sts interrupt. Read only.
  [2:0] dma_egr_pend_que_ovf_err — When set allows the corresponding bit in the raw_status register to generate the intr1_sts interrupt. Read only.
0x180F8 DIO2_ee_dma_egr_a_EV1_Enable_Set wo — (1 of 1, stride 0)
  [12] si_ing_iq_fifo_full_info — Sets the corresponding bit in the intr1_status register when set. Write only, self-clears.
  [10:8] dma_egr_xfer_done_info — Sets the corresponding bit in the intr1_status register when set. Write only, self-clears.
  [6:4] dma_egr_prog_err — Sets the corresponding bit in the intr1_status register when set. Write only, self-clears.
  [2:0] dma_egr_pend_que_ovf_err — Sets the corresponding bit in the intr1_status register when set. Write only, self-clears.
0x180FC DIO2_ee_dma_egr_a_EV1_Enable_Clear wo — (1 of 1, stride 0)
  [12] si_ing_iq_fifo_full_info — Clears the corresponding bit in the intr1_status register when set. Write only, self-clears.
  [10:8] dma_egr_xfer_done_info — Clears the corresponding bit in the intr1_status register when set. Write only, self-clears.
  [6:4] dma_egr_prog_err — Clears the corresponding bit in the intr1_status register when set. Write only, self-clears.
  [2:0] dma_egr_pend_que_ovf_err — Clears the corresponding bit in the intr1_status register when set. Write only, self-clears.
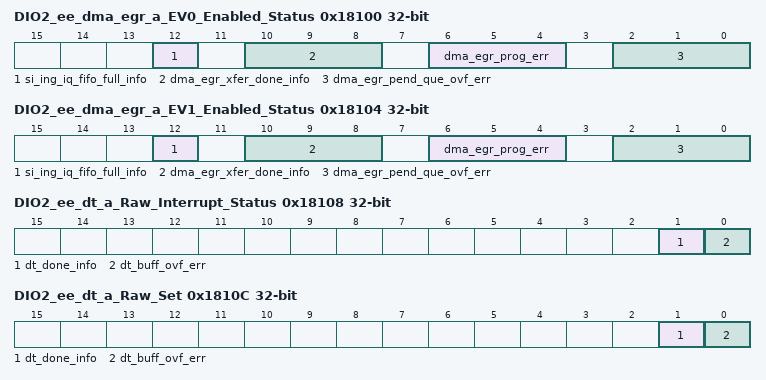
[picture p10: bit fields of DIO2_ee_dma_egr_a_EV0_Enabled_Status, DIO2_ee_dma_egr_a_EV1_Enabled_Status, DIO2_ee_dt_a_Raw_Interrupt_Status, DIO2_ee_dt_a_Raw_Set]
0x18100 DIO2_ee_dma_egr_a_EV0_Enabled_Status — (1 of 1, stride 0)
  [12] si_ing_iq_fifo_full_info — AND-ed raw_status bits with the corresponding bit in the enable_status register. Read only.
  [10:8] dma_egr_xfer_done_info — AND-ed raw_status bits with the corresponding bit in the enable_status register. Read only.
  [6:4] dma_egr_prog_err — AND-ed raw_status bits with the corresponding bit in the enable_status register. Read only.
  [2:0] dma_egr_pend_que_ovf_err — AND-ed raw_status bits with the corresponding bit in the enable_status register. Read only.
0x18104 DIO2_ee_dma_egr_a_EV1_Enabled_Status — (1 of 1, stride 0)
  [12] si_ing_iq_fifo_full_info — AND-ed raw_status bits with the corresponding bit in the intr1_status register. Read only.
  [10:8] dma_egr_xfer_done_info — AND-ed raw_status bits with the corresponding bit in the intr1_status register. Read only.
  [6:4] dma_egr_prog_err — AND-ed raw_status bits with the corresponding bit in the intr1_status register. Read only.
  [2:0] dma_egr_pend_que_ovf_err — AND-ed raw_status bits with the corresponding bit in the intr1_status register. Read only.
0x18108 DIO2_ee_dt_a_Raw_Interrupt_Status — (1 of 1, stride 0)
  [1] dt_done_info — Data Trace one shot capture done info
  [0] dt_buff_ovf_err — Data Trace buffer overflow error
0x1810C DIO2_ee_dt_a_Raw_Set wo — (1 of 1, stride 0)
  [1] dt_done_info — Sets the corresponding bit in the raw_status register when set. Write only, self-clears.
  [0] dt_buff_ovf_err — Sets the corresponding bit in the raw_status register when set. Write only, self-clears.
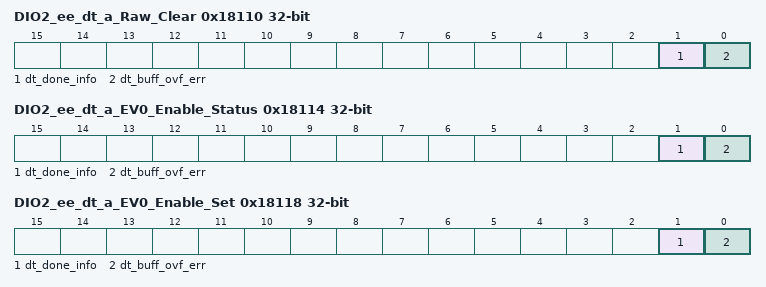
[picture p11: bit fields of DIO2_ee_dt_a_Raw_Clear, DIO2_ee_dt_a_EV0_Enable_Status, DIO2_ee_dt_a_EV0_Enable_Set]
0x18110 DIO2_ee_dt_a_Raw_Clear wo — (1 of 1, stride 0)
  [1] dt_done_info — Clears the corresponding bit in the raw_status register when set. Write only, self-clears.
  [0] dt_buff_ovf_err — Clears the corresponding bit in the raw_status register when set. Write only, self-clears.
0x18114 DIO2_ee_dt_a_EV0_Enable_Status — (1 of 1, stride 0)
  [1] dt_done_info — When set allows the corresponding bit in the raw_status register to generate the intr_sts interrupt. Read only.
  [0] dt_buff_ovf_err — When set allows the corresponding bit in the raw_status register to generate the intr_sts interrupt. Read only.
0x18118 DIO2_ee_dt_a_EV0_Enable_Set wo — (1 of 1, stride 0)
  [1] dt_done_info — Sets the corresponding bit in the enable register when set. Write only, self-clears.
  [0] dt_buff_ovf_err — Sets the corresponding bit in the enable register when set. Write only, self-clears.
